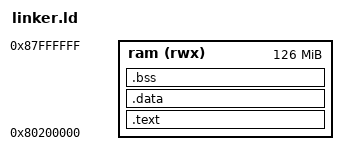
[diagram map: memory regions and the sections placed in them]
/* GENERATED BY GEMINI */
OUTPUT_ARCH( "riscv" )
ENTRY( _start )

MEMORY
{
  ram   (rwx) : ORIGIN = 0x80200000, LENGTH = 128M - 0x200000
}

SECTIONS
{
  .text :
  {
    KEEP(*(.text.init))
    *(.text .text.*)
    *(.rodata .rodata.*)
  } > ram

  .data :
  {
    *(.data .data.*)
  } > ram

  .bss :
  {
    _bss_start = .;
    *(.bss .bss.*)
    *(COMMON)
    _bss_end = .;
  } > ram

  _end = .;
  PROVIDE(end = .);

  . = ALIGN(16);
  _stack_top = ORIGIN(ram) + LENGTH(ram);
  PROVIDE(_kernel_stack_top = _stack_top); /* Add PROVIDE for C compatibility */
}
